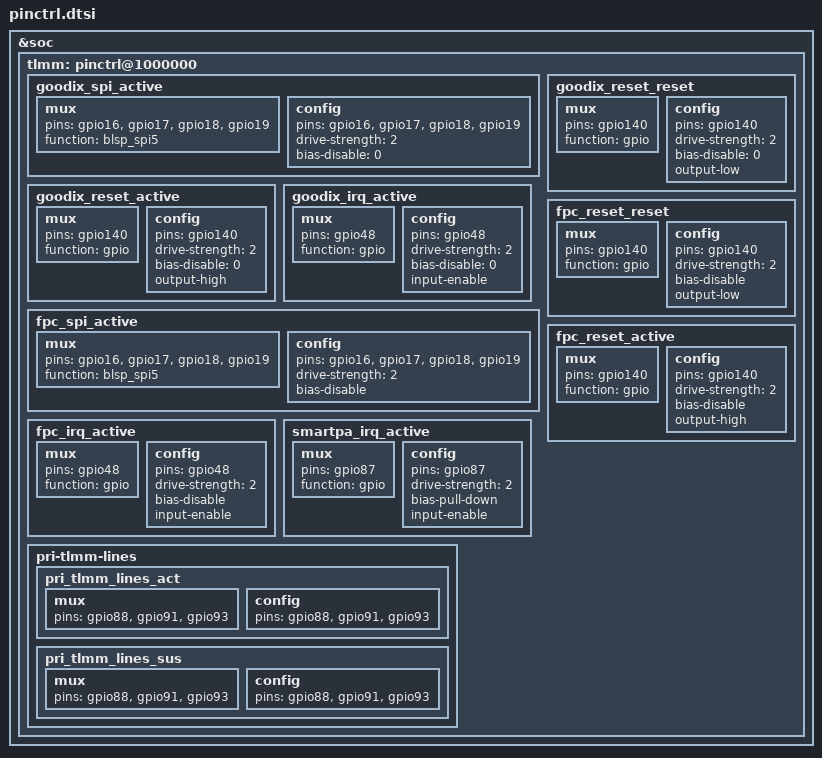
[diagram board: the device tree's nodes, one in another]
/*
 * Copyright (c) 2015-2017, The Linux Foundation. All rights reserved.
 * Copyright (C) 2019 XiaoMi, Inc.
 *
 * This program is free software; you can redistribute it and/or modify
 * it under the terms of the GNU General Public License version 2 and
 * only version 2 as published by the Free Software Foundation.
 *
 * This program is distributed in the hope that it will be useful,
 * but WITHOUT ANY WARRANTY; without even the implied warranty of
 * MERCHANTABILITY or FITNESS FOR A PARTICULAR PURPOSE.  See the
 * GNU General Public License for more details.
 */

/* msm8953-pinctrl */
&soc {
	tlmm: pinctrl@1000000 {
		/*fp gpio of gooid & fpc */
		goodix_spi_active: goodix_spi_active{
			mux {
				pins = "gpio16", "gpio17", "gpio18", "gpio19";
				function = "blsp_spi5";
			};
			config {
				pins = "gpio16", "gpio17", "gpio18", "gpio19";
				drive-strength = <2>;
				bias-disable = <0>;
			};
		};
		goodix_reset_reset: goodix_reset_reset{
			mux {
				pins = "gpio140";
				function = "gpio";
			};
			config {
				pins = "gpio140";
				drive-strength = <2>;
				bias-disable = <0>;
				output-low;
			};
		};
		goodix_reset_active: goodix_reset_active{
			mux {
				pins = "gpio140";
				function = "gpio";
			};
			config {
				pins = "gpio140";
				drive-strength = <2>;
				bias-disable = <0>;
				output-high;
			};
		};
		goodix_irq_active: goodix_irq_active {
			mux {
				pins = "gpio48";
				function = "gpio";
			};
			config {
				pins = "gpio48";
				drive-strength = <2>;
				bias-disable = <0>;
				input-enable;
			};
		};

		/* fingerprint pin function */
		fpc_spi_active: fpc_spi_active {
			mux {
				pins = "gpio16", "gpio17", "gpio18", "gpio19";
				function = "blsp_spi5";
			};

			config {
				pins = "gpio16", "gpio17", "gpio18", "gpio19";
				drive-strength = <2>;
				bias-disable;
			};
		};
		fpc_reset_reset: fpc_reset_reset {
			mux {
				pins = "gpio140";
				function = "gpio";
			};
			config {
				pins = "gpio140";
				drive-strength = <2>;
				bias-disable;
				output-low;
			};
		};
		fpc_reset_active: fpc_reset_active {
			mux {
				pins = "gpio140";
				function = "gpio";
			};
			config {
				pins = "gpio140";
				drive-strength = <2>;
				bias-disable;
				output-high;
			};
		};
		fpc_irq_active: fpc_irq_active {
			mux {
				pins = "gpio48";
				function = "gpio";
			};
			config {
				pins = "gpio48";
				drive-strength = <2>;
				bias-disable;
				input-enable;
			};
		};

		smartpa_irq_active: smartpa_irq_active {
			mux {
				pins = "gpio87";
				function = "gpio";
			};
			config {
				pins = "gpio87";
				drive-strength = <2>;
				bias-pull-down;
				input-enable;
			};
		};
		pri-tlmm-lines {
			pri_tlmm_lines_act: pri_tlmm_lines_act {
				mux {
					pins = "gpio88", "gpio91", "gpio93";
				};
				config {
					pins = "gpio88", "gpio91", "gpio93";
				};
			};
			pri_tlmm_lines_sus: pri_tlmm_lines_sus {
				mux {
					pins = "gpio88", "gpio91", "gpio93";
				};
				config {
					pins = "gpio88", "gpio91", "gpio93";
				};
			};
		};
	};
};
